VERSION ""

NS_ :

BS_:

BU_: XXX

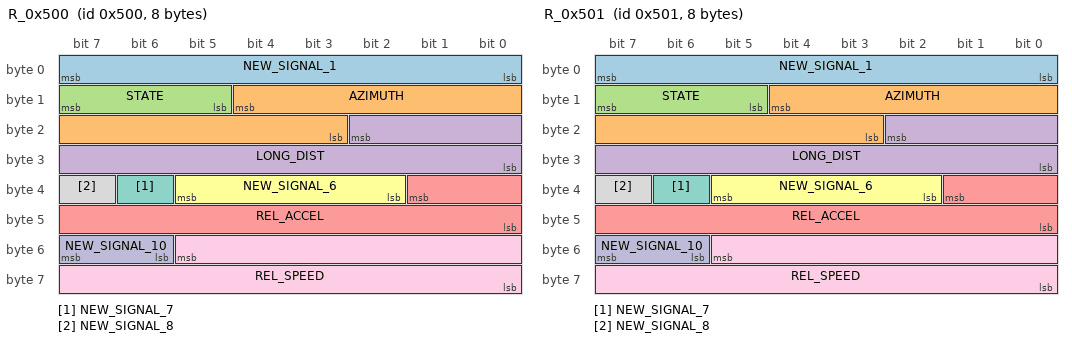
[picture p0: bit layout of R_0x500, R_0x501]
BO_ 1280 R_0x500: 8 XXX
 SG_ NEW_SIGNAL_1 : 7|8@0- (1,0) [-128|127] "" XXX
 SG_ AZIMUTH : 12|10@0- (0.2,0) [-102.4|102.2] "" XXX
 SG_ STATE : 15|3@0+ (1,0) [0|7] "" XXX
 SG_ LONG_DIST : 18|11@0+ (0.1,0) [0|204.7] "" XXX
 SG_ REL_ACCEL : 33|10@0- (0.02,0) [-10.24|10.22] "" XXX
 SG_ NEW_SIGNAL_6 : 37|4@0+ (1,0) [0|255] "" XXX
 SG_ NEW_SIGNAL_7 : 38|1@0+ (1,0) [0|1] "" XXX
 SG_ NEW_SIGNAL_8 : 39|1@0+ (1,0) [0|1] "" XXX
 SG_ REL_SPEED : 53|14@0- (0.01,0) [-81.92|81.92] "" XXX
 SG_ NEW_SIGNAL_10 : 55|2@0+ (1,0) [0|3] "" XXX

BO_ 1281 R_0x501: 8 XXX
 SG_ NEW_SIGNAL_1 : 7|8@0- (1,0) [-128|127] "" XXX
 SG_ AZIMUTH : 12|10@0- (0.2,0) [-102.4|102.2] "" XXX
 SG_ STATE : 15|3@0+ (1,0) [0|7] "" XXX
 SG_ LONG_DIST : 18|11@0+ (0.1,0) [0|204.7] "" XXX
 SG_ REL_ACCEL : 33|10@0- (0.02,0) [-10.24|10.22] "" XXX
 SG_ NEW_SIGNAL_6 : 37|4@0+ (1,0) [0|255] "" XXX
 SG_ NEW_SIGNAL_7 : 38|1@0+ (1,0) [0|1] "" XXX
 SG_ NEW_SIGNAL_8 : 39|1@0+ (1,0) [0|1] "" XXX
 SG_ REL_SPEED : 53|14@0- (0.01,0) [-81.92|81.92] "" XXX
 SG_ NEW_SIGNAL_10 : 55|2@0+ (1,0) [0|3] "" XXX

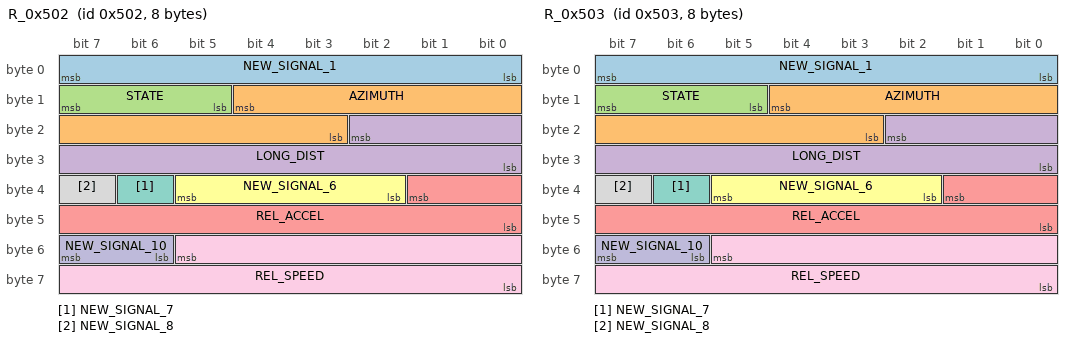
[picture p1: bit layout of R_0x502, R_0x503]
BO_ 1282 R_0x502: 8 XXX
 SG_ NEW_SIGNAL_1 : 7|8@0- (1,0) [-128|127] "" XXX
 SG_ AZIMUTH : 12|10@0- (0.2,0) [-102.4|102.2] "" XXX
 SG_ STATE : 15|3@0+ (1,0) [0|7] "" XXX
 SG_ LONG_DIST : 18|11@0+ (0.1,0) [0|204.7] "" XXX
 SG_ REL_ACCEL : 33|10@0- (0.02,0) [-10.24|10.22] "" XXX
 SG_ NEW_SIGNAL_6 : 37|4@0+ (1,0) [0|255] "" XXX
 SG_ NEW_SIGNAL_7 : 38|1@0+ (1,0) [0|1] "" XXX
 SG_ NEW_SIGNAL_8 : 39|1@0+ (1,0) [0|1] "" XXX
 SG_ REL_SPEED : 53|14@0- (0.01,0) [-81.92|81.92] "" XXX
 SG_ NEW_SIGNAL_10 : 55|2@0+ (1,0) [0|3] "" XXX

BO_ 1283 R_0x503: 8 XXX
 SG_ NEW_SIGNAL_1 : 7|8@0- (1,0) [-128|127] "" XXX
 SG_ AZIMUTH : 12|10@0- (0.2,0) [-102.4|102.2] "" XXX
 SG_ STATE : 15|3@0+ (1,0) [0|7] "" XXX
 SG_ LONG_DIST : 18|11@0+ (0.1,0) [0|204.7] "" XXX
 SG_ REL_ACCEL : 33|10@0- (0.02,0) [-10.24|10.22] "" XXX
 SG_ NEW_SIGNAL_6 : 37|4@0+ (1,0) [0|255] "" XXX
 SG_ NEW_SIGNAL_7 : 38|1@0+ (1,0) [0|1] "" XXX
 SG_ NEW_SIGNAL_8 : 39|1@0+ (1,0) [0|1] "" XXX
 SG_ REL_SPEED : 53|14@0- (0.01,0) [-81.92|81.92] "" XXX
 SG_ NEW_SIGNAL_10 : 55|2@0+ (1,0) [0|3] "" XXX

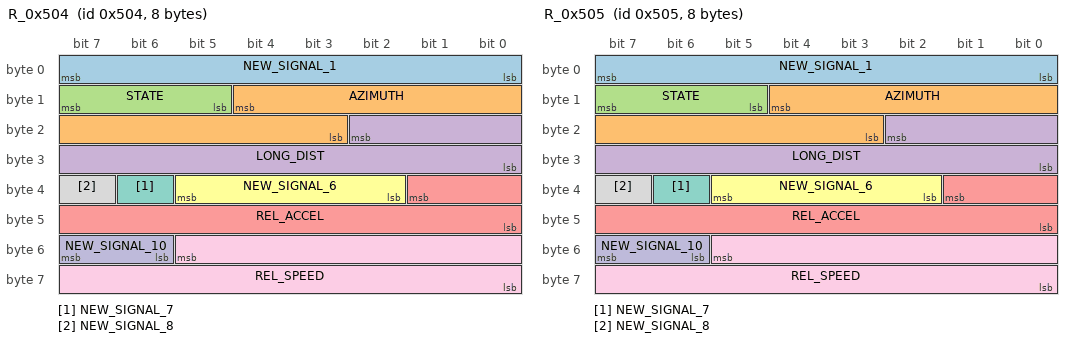
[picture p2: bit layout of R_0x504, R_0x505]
BO_ 1284 R_0x504: 8 XXX
 SG_ NEW_SIGNAL_1 : 7|8@0- (1,0) [-128|127] "" XXX
 SG_ AZIMUTH : 12|10@0- (0.2,0) [-102.4|102.2] "" XXX
 SG_ STATE : 15|3@0+ (1,0) [0|7] "" XXX
 SG_ LONG_DIST : 18|11@0+ (0.1,0) [0|204.7] "" XXX
 SG_ REL_ACCEL : 33|10@0- (0.02,0) [-10.24|10.22] "" XXX
 SG_ NEW_SIGNAL_6 : 37|4@0+ (1,0) [0|255] "" XXX
 SG_ NEW_SIGNAL_7 : 38|1@0+ (1,0) [0|1] "" XXX
 SG_ NEW_SIGNAL_8 : 39|1@0+ (1,0) [0|1] "" XXX
 SG_ REL_SPEED : 53|14@0- (0.01,0) [-81.92|81.92] "" XXX
 SG_ NEW_SIGNAL_10 : 55|2@0+ (1,0) [0|3] "" XXX

BO_ 1285 R_0x505: 8 XXX
 SG_ NEW_SIGNAL_1 : 7|8@0- (1,0) [-128|127] "" XXX
 SG_ AZIMUTH : 12|10@0- (0.2,0) [-102.4|102.2] "" XXX
 SG_ STATE : 15|3@0+ (1,0) [0|7] "" XXX
 SG_ LONG_DIST : 18|11@0+ (0.1,0) [0|204.7] "" XXX
 SG_ REL_ACCEL : 33|10@0- (0.02,0) [-10.24|10.22] "" XXX
 SG_ NEW_SIGNAL_6 : 37|4@0+ (1,0) [0|255] "" XXX
 SG_ NEW_SIGNAL_7 : 38|1@0+ (1,0) [0|1] "" XXX
 SG_ NEW_SIGNAL_8 : 39|1@0+ (1,0) [0|1] "" XXX
 SG_ REL_SPEED : 53|14@0- (0.01,0) [-81.92|81.92] "" XXX
 SG_ NEW_SIGNAL_10 : 55|2@0+ (1,0) [0|3] "" XXX

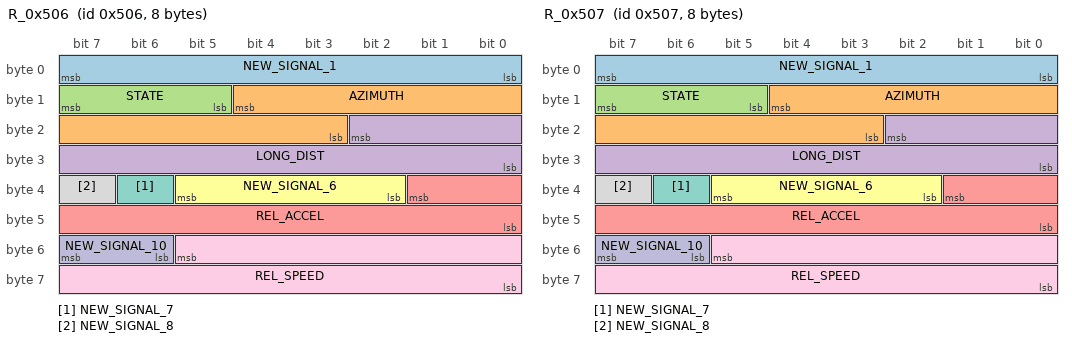
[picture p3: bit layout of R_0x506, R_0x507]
BO_ 1286 R_0x506: 8 XXX
 SG_ NEW_SIGNAL_1 : 7|8@0- (1,0) [-128|127] "" XXX
 SG_ AZIMUTH : 12|10@0- (0.2,0) [-102.4|102.2] "" XXX
 SG_ STATE : 15|3@0+ (1,0) [0|7] "" XXX
 SG_ LONG_DIST : 18|11@0+ (0.1,0) [0|204.7] "" XXX
 SG_ REL_ACCEL : 33|10@0- (0.02,0) [-10.24|10.22] "" XXX
 SG_ NEW_SIGNAL_6 : 37|4@0+ (1,0) [0|255] "" XXX
 SG_ NEW_SIGNAL_7 : 38|1@0+ (1,0) [0|1] "" XXX
 SG_ NEW_SIGNAL_8 : 39|1@0+ (1,0) [0|1] "" XXX
 SG_ REL_SPEED : 53|14@0- (0.01,0) [-81.92|81.92] "" XXX
 SG_ NEW_SIGNAL_10 : 55|2@0+ (1,0) [0|3] "" XXX

BO_ 1287 R_0x507: 8 XXX
 SG_ NEW_SIGNAL_1 : 7|8@0- (1,0) [-128|127] "" XXX
 SG_ AZIMUTH : 12|10@0- (0.2,0) [-102.4|102.2] "" XXX
 SG_ STATE : 15|3@0+ (1,0) [0|7] "" XXX
 SG_ LONG_DIST : 18|11@0+ (0.1,0) [0|204.7] "" XXX
 SG_ REL_ACCEL : 33|10@0- (0.02,0) [-10.24|10.22] "" XXX
 SG_ NEW_SIGNAL_6 : 37|4@0+ (1,0) [0|255] "" XXX
 SG_ NEW_SIGNAL_7 : 38|1@0+ (1,0) [0|1] "" XXX
 SG_ NEW_SIGNAL_8 : 39|1@0+ (1,0) [0|1] "" XXX
 SG_ REL_SPEED : 53|14@0- (0.01,0) [-81.92|81.92] "" XXX
 SG_ NEW_SIGNAL_10 : 55|2@0+ (1,0) [0|3] "" XXX

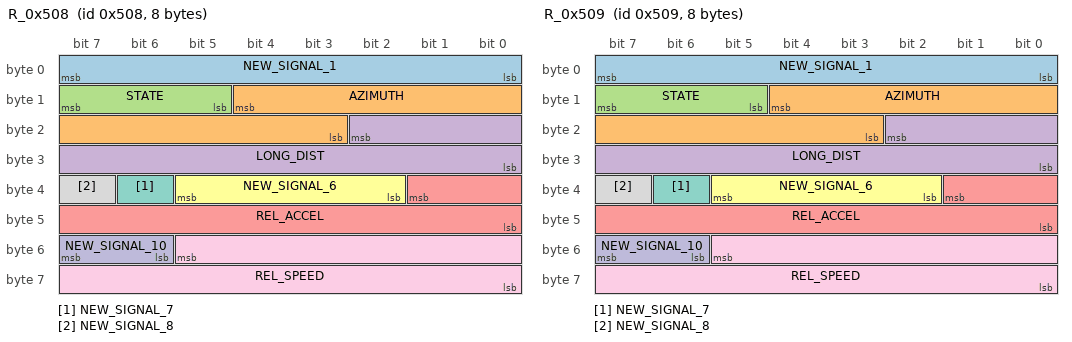
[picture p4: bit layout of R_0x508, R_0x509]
BO_ 1288 R_0x508: 8 XXX
 SG_ NEW_SIGNAL_1 : 7|8@0- (1,0) [-128|127] "" XXX
 SG_ AZIMUTH : 12|10@0- (0.2,0) [-102.4|102.2] "" XXX
 SG_ STATE : 15|3@0+ (1,0) [0|7] "" XXX
 SG_ LONG_DIST : 18|11@0+ (0.1,0) [0|204.7] "" XXX
 SG_ REL_ACCEL : 33|10@0- (0.02,0) [-10.24|10.22] "" XXX
 SG_ NEW_SIGNAL_6 : 37|4@0+ (1,0) [0|255] "" XXX
 SG_ NEW_SIGNAL_7 : 38|1@0+ (1,0) [0|1] "" XXX
 SG_ NEW_SIGNAL_8 : 39|1@0+ (1,0) [0|1] "" XXX
 SG_ REL_SPEED : 53|14@0- (0.01,0) [-81.92|81.92] "" XXX
 SG_ NEW_SIGNAL_10 : 55|2@0+ (1,0) [0|3] "" XXX

BO_ 1289 R_0x509: 8 XXX
 SG_ NEW_SIGNAL_1 : 7|8@0- (1,0) [-128|127] "" XXX
 SG_ AZIMUTH : 12|10@0- (0.2,0) [-102.4|102.2] "" XXX
 SG_ STATE : 15|3@0+ (1,0) [0|7] "" XXX
 SG_ LONG_DIST : 18|11@0+ (0.1,0) [0|204.7] "" XXX
 SG_ REL_ACCEL : 33|10@0- (0.02,0) [-10.24|10.22] "" XXX
 SG_ NEW_SIGNAL_6 : 37|4@0+ (1,0) [0|255] "" XXX
 SG_ NEW_SIGNAL_7 : 38|1@0+ (1,0) [0|1] "" XXX
 SG_ NEW_SIGNAL_8 : 39|1@0+ (1,0) [0|1] "" XXX
 SG_ REL_SPEED : 53|14@0- (0.01,0) [-81.92|81.92] "" XXX
 SG_ NEW_SIGNAL_10 : 55|2@0+ (1,0) [0|3] "" XXX

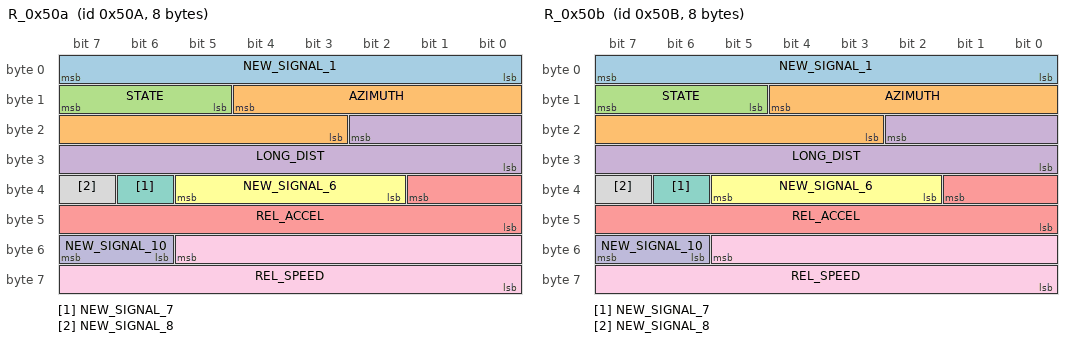
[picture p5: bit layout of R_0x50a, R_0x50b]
BO_ 1290 R_0x50a: 8 XXX
 SG_ NEW_SIGNAL_1 : 7|8@0- (1,0) [-128|127] "" XXX
 SG_ AZIMUTH : 12|10@0- (0.2,0) [-102.4|102.2] "" XXX
 SG_ STATE : 15|3@0+ (1,0) [0|7] "" XXX
 SG_ LONG_DIST : 18|11@0+ (0.1,0) [0|204.7] "" XXX
 SG_ REL_ACCEL : 33|10@0- (0.02,0) [-10.24|10.22] "" XXX
 SG_ NEW_SIGNAL_6 : 37|4@0+ (1,0) [0|255] "" XXX
 SG_ NEW_SIGNAL_7 : 38|1@0+ (1,0) [0|1] "" XXX
 SG_ NEW_SIGNAL_8 : 39|1@0+ (1,0) [0|1] "" XXX
 SG_ REL_SPEED : 53|14@0- (0.01,0) [-81.92|81.92] "" XXX
 SG_ NEW_SIGNAL_10 : 55|2@0+ (1,0) [0|3] "" XXX

BO_ 1291 R_0x50b: 8 XXX
 SG_ NEW_SIGNAL_1 : 7|8@0- (1,0) [-128|127] "" XXX
 SG_ AZIMUTH : 12|10@0- (0.2,0) [-102.4|102.2] "" XXX
 SG_ STATE : 15|3@0+ (1,0) [0|7] "" XXX
 SG_ LONG_DIST : 18|11@0+ (0.1,0) [0|204.7] "" XXX
 SG_ REL_ACCEL : 33|10@0- (0.02,0) [-10.24|10.22] "" XXX
 SG_ NEW_SIGNAL_6 : 37|4@0+ (1,0) [0|255] "" XXX
 SG_ NEW_SIGNAL_7 : 38|1@0+ (1,0) [0|1] "" XXX
 SG_ NEW_SIGNAL_8 : 39|1@0+ (1,0) [0|1] "" XXX
 SG_ REL_SPEED : 53|14@0- (0.01,0) [-81.92|81.92] "" XXX
 SG_ NEW_SIGNAL_10 : 55|2@0+ (1,0) [0|3] "" XXX

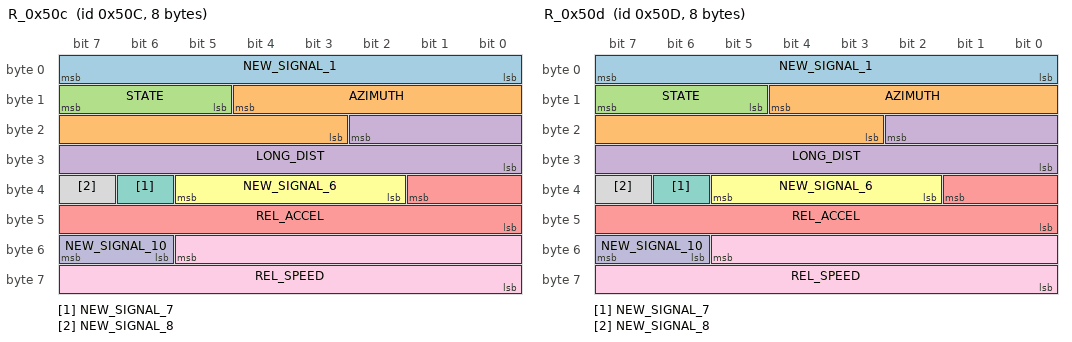
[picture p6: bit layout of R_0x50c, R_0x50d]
BO_ 1292 R_0x50c: 8 XXX
 SG_ NEW_SIGNAL_1 : 7|8@0- (1,0) [-128|127] "" XXX
 SG_ AZIMUTH : 12|10@0- (0.2,0) [-102.4|102.2] "" XXX
 SG_ STATE : 15|3@0+ (1,0) [0|7] "" XXX
 SG_ LONG_DIST : 18|11@0+ (0.1,0) [0|204.7] "" XXX
 SG_ REL_ACCEL : 33|10@0- (0.02,0) [-10.24|10.22] "" XXX
 SG_ NEW_SIGNAL_6 : 37|4@0+ (1,0) [0|255] "" XXX
 SG_ NEW_SIGNAL_7 : 38|1@0+ (1,0) [0|1] "" XXX
 SG_ NEW_SIGNAL_8 : 39|1@0+ (1,0) [0|1] "" XXX
 SG_ REL_SPEED : 53|14@0- (0.01,0) [-81.92|81.92] "" XXX
 SG_ NEW_SIGNAL_10 : 55|2@0+ (1,0) [0|3] "" XXX

BO_ 1293 R_0x50d: 8 XXX
 SG_ NEW_SIGNAL_1 : 7|8@0- (1,0) [-128|127] "" XXX
 SG_ AZIMUTH : 12|10@0- (0.2,0) [-102.4|102.2] "" XXX
 SG_ STATE : 15|3@0+ (1,0) [0|7] "" XXX
 SG_ LONG_DIST : 18|11@0+ (0.1,0) [0|204.7] "" XXX
 SG_ REL_ACCEL : 33|10@0- (0.02,0) [-10.24|10.22] "" XXX
 SG_ NEW_SIGNAL_6 : 37|4@0+ (1,0) [0|255] "" XXX
 SG_ NEW_SIGNAL_7 : 38|1@0+ (1,0) [0|1] "" XXX
 SG_ NEW_SIGNAL_8 : 39|1@0+ (1,0) [0|1] "" XXX
 SG_ REL_SPEED : 53|14@0- (0.01,0) [-81.92|81.92] "" XXX
 SG_ NEW_SIGNAL_10 : 55|2@0+ (1,0) [0|3] "" XXX

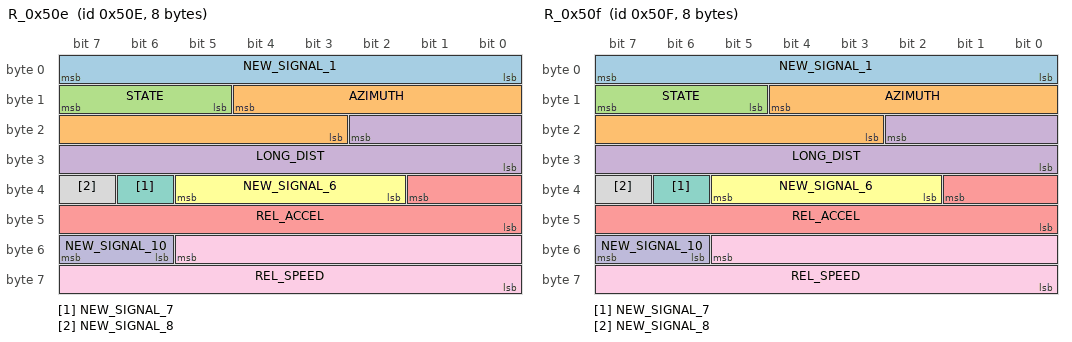
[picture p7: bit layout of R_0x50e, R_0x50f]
BO_ 1294 R_0x50e: 8 XXX
 SG_ NEW_SIGNAL_1 : 7|8@0- (1,0) [-128|127] "" XXX
 SG_ AZIMUTH : 12|10@0- (0.2,0) [-102.4|102.2] "" XXX
 SG_ STATE : 15|3@0+ (1,0) [0|7] "" XXX
 SG_ LONG_DIST : 18|11@0+ (0.1,0) [0|204.7] "" XXX
 SG_ REL_ACCEL : 33|10@0- (0.02,0) [-10.24|10.22] "" XXX
 SG_ NEW_SIGNAL_6 : 37|4@0+ (1,0) [0|255] "" XXX
 SG_ NEW_SIGNAL_7 : 38|1@0+ (1,0) [0|1] "" XXX
 SG_ NEW_SIGNAL_8 : 39|1@0+ (1,0) [0|1] "" XXX
 SG_ REL_SPEED : 53|14@0- (0.01,0) [-81.92|81.92] "" XXX
 SG_ NEW_SIGNAL_10 : 55|2@0+ (1,0) [0|3] "" XXX

BO_ 1295 R_0x50f: 8 XXX
 SG_ NEW_SIGNAL_1 : 7|8@0- (1,0) [-128|127] "" XXX
 SG_ AZIMUTH : 12|10@0- (0.2,0) [-102.4|102.2] "" XXX
 SG_ STATE : 15|3@0+ (1,0) [0|7] "" XXX
 SG_ LONG_DIST : 18|11@0+ (0.1,0) [0|204.7] "" XXX
 SG_ REL_ACCEL : 33|10@0- (0.02,0) [-10.24|10.22] "" XXX
 SG_ NEW_SIGNAL_6 : 37|4@0+ (1,0) [0|255] "" XXX
 SG_ NEW_SIGNAL_7 : 38|1@0+ (1,0) [0|1] "" XXX
 SG_ NEW_SIGNAL_8 : 39|1@0+ (1,0) [0|1] "" XXX
 SG_ REL_SPEED : 53|14@0- (0.01,0) [-81.92|81.92] "" XXX
 SG_ NEW_SIGNAL_10 : 55|2@0+ (1,0) [0|3] "" XXX

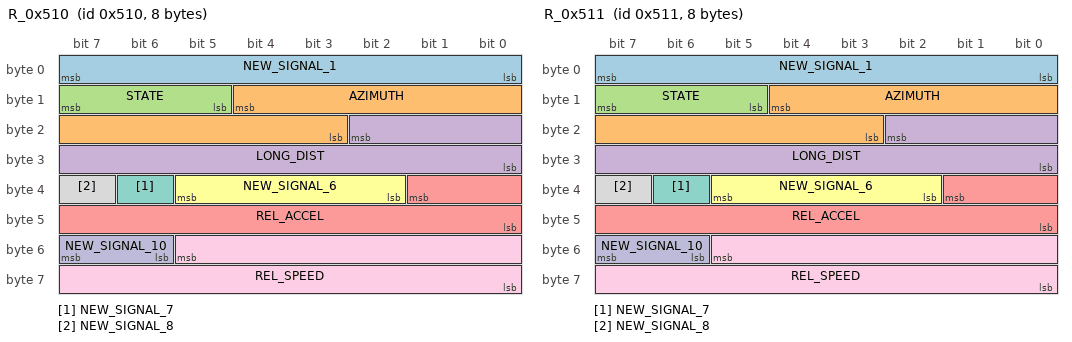
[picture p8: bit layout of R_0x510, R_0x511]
BO_ 1296 R_0x510: 8 XXX
 SG_ NEW_SIGNAL_1 : 7|8@0- (1,0) [-128|127] "" XXX
 SG_ AZIMUTH : 12|10@0- (0.2,0) [-102.4|102.2] "" XXX
 SG_ STATE : 15|3@0+ (1,0) [0|7] "" XXX
 SG_ LONG_DIST : 18|11@0+ (0.1,0) [0|204.7] "" XXX
 SG_ REL_ACCEL : 33|10@0- (0.02,0) [-10.24|10.22] "" XXX
 SG_ NEW_SIGNAL_6 : 37|4@0+ (1,0) [0|255] "" XXX
 SG_ NEW_SIGNAL_7 : 38|1@0+ (1,0) [0|1] "" XXX
 SG_ NEW_SIGNAL_8 : 39|1@0+ (1,0) [0|1] "" XXX
 SG_ REL_SPEED : 53|14@0- (0.01,0) [-81.92|81.92] "" XXX
 SG_ NEW_SIGNAL_10 : 55|2@0+ (1,0) [0|3] "" XXX

BO_ 1297 R_0x511: 8 XXX
 SG_ NEW_SIGNAL_1 : 7|8@0- (1,0) [-128|127] "" XXX
 SG_ AZIMUTH : 12|10@0- (0.2,0) [-102.4|102.2] "" XXX
 SG_ STATE : 15|3@0+ (1,0) [0|7] "" XXX
 SG_ LONG_DIST : 18|11@0+ (0.1,0) [0|204.7] "" XXX
 SG_ REL_ACCEL : 33|10@0- (0.02,0) [-10.24|10.22] "" XXX
 SG_ NEW_SIGNAL_6 : 37|4@0+ (1,0) [0|255] "" XXX
 SG_ NEW_SIGNAL_7 : 38|1@0+ (1,0) [0|1] "" XXX
 SG_ NEW_SIGNAL_8 : 39|1@0+ (1,0) [0|1] "" XXX
 SG_ REL_SPEED : 53|14@0- (0.01,0) [-81.92|81.92] "" XXX
 SG_ NEW_SIGNAL_10 : 55|2@0+ (1,0) [0|3] "" XXX

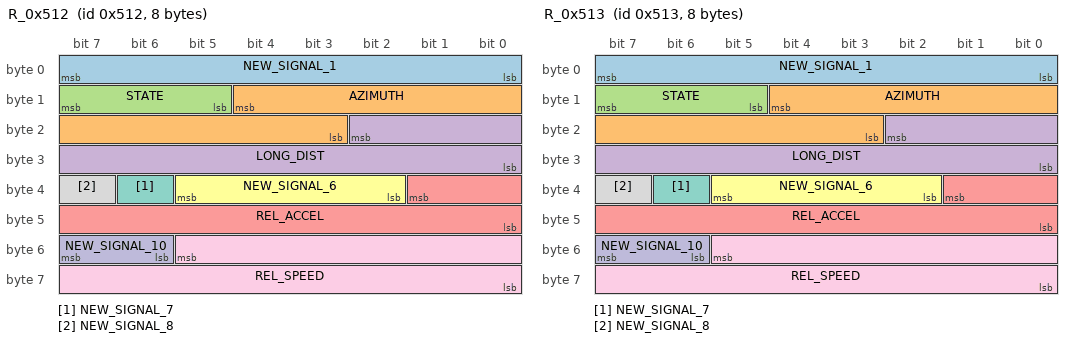
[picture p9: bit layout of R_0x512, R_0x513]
BO_ 1298 R_0x512: 8 XXX
 SG_ NEW_SIGNAL_1 : 7|8@0- (1,0) [-128|127] "" XXX
 SG_ AZIMUTH : 12|10@0- (0.2,0) [-102.4|102.2] "" XXX
 SG_ STATE : 15|3@0+ (1,0) [0|7] "" XXX
 SG_ LONG_DIST : 18|11@0+ (0.1,0) [0|204.7] "" XXX
 SG_ REL_ACCEL : 33|10@0- (0.02,0) [-10.24|10.22] "" XXX
 SG_ NEW_SIGNAL_6 : 37|4@0+ (1,0) [0|255] "" XXX
 SG_ NEW_SIGNAL_7 : 38|1@0+ (1,0) [0|1] "" XXX
 SG_ NEW_SIGNAL_8 : 39|1@0+ (1,0) [0|1] "" XXX
 SG_ REL_SPEED : 53|14@0- (0.01,0) [-81.92|81.92] "" XXX
 SG_ NEW_SIGNAL_10 : 55|2@0+ (1,0) [0|3] "" XXX

BO_ 1299 R_0x513: 8 XXX
 SG_ NEW_SIGNAL_1 : 7|8@0- (1,0) [-128|127] "" XXX
 SG_ AZIMUTH : 12|10@0- (0.2,0) [-102.4|102.2] "" XXX
 SG_ STATE : 15|3@0+ (1,0) [0|7] "" XXX
 SG_ LONG_DIST : 18|11@0+ (0.1,0) [0|204.7] "" XXX
 SG_ REL_ACCEL : 33|10@0- (0.02,0) [-10.24|10.22] "" XXX
 SG_ NEW_SIGNAL_6 : 37|4@0+ (1,0) [0|255] "" XXX
 SG_ NEW_SIGNAL_7 : 38|1@0+ (1,0) [0|1] "" XXX
 SG_ NEW_SIGNAL_8 : 39|1@0+ (1,0) [0|1] "" XXX
 SG_ REL_SPEED : 53|14@0- (0.01,0) [-81.92|81.92] "" XXX
 SG_ NEW_SIGNAL_10 : 55|2@0+ (1,0) [0|3] "" XXX

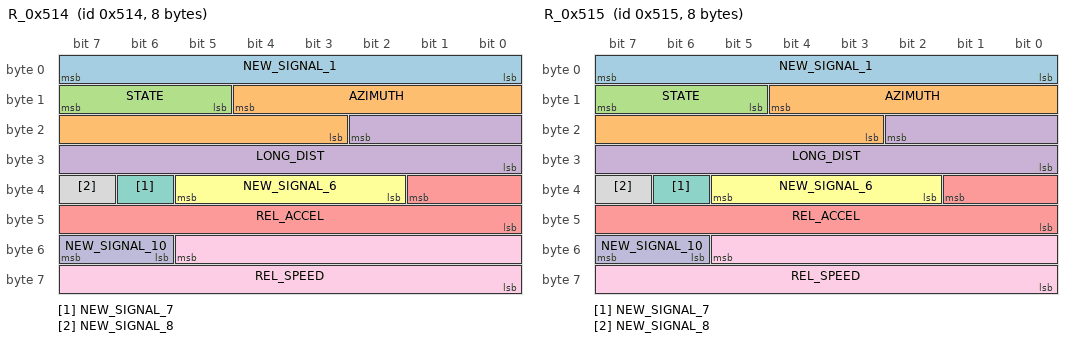
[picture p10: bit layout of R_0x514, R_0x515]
BO_ 1300 R_0x514: 8 XXX
 SG_ NEW_SIGNAL_1 : 7|8@0- (1,0) [-128|127] "" XXX
 SG_ AZIMUTH : 12|10@0- (0.2,0) [-102.4|102.2] "" XXX
 SG_ STATE : 15|3@0+ (1,0) [0|7] "" XXX
 SG_ LONG_DIST : 18|11@0+ (0.1,0) [0|204.7] "" XXX
 SG_ REL_ACCEL : 33|10@0- (0.02,0) [-10.24|10.22] "" XXX
 SG_ NEW_SIGNAL_6 : 37|4@0+ (1,0) [0|255] "" XXX
 SG_ NEW_SIGNAL_7 : 38|1@0+ (1,0) [0|1] "" XXX
 SG_ NEW_SIGNAL_8 : 39|1@0+ (1,0) [0|1] "" XXX
 SG_ REL_SPEED : 53|14@0- (0.01,0) [-81.92|81.92] "" XXX
 SG_ NEW_SIGNAL_10 : 55|2@0+ (1,0) [0|3] "" XXX

BO_ 1301 R_0x515: 8 XXX
 SG_ NEW_SIGNAL_1 : 7|8@0- (1,0) [-128|127] "" XXX
 SG_ AZIMUTH : 12|10@0- (0.2,0) [-102.4|102.2] "" XXX
 SG_ STATE : 15|3@0+ (1,0) [0|7] "" XXX
 SG_ LONG_DIST : 18|11@0+ (0.1,0) [0|204.7] "" XXX
 SG_ REL_ACCEL : 33|10@0- (0.02,0) [-10.24|10.22] "" XXX
 SG_ NEW_SIGNAL_6 : 37|4@0+ (1,0) [0|255] "" XXX
 SG_ NEW_SIGNAL_7 : 38|1@0+ (1,0) [0|1] "" XXX
 SG_ NEW_SIGNAL_8 : 39|1@0+ (1,0) [0|1] "" XXX
 SG_ REL_SPEED : 53|14@0- (0.01,0) [-81.92|81.92] "" XXX
 SG_ NEW_SIGNAL_10 : 55|2@0+ (1,0) [0|3] "" XXX

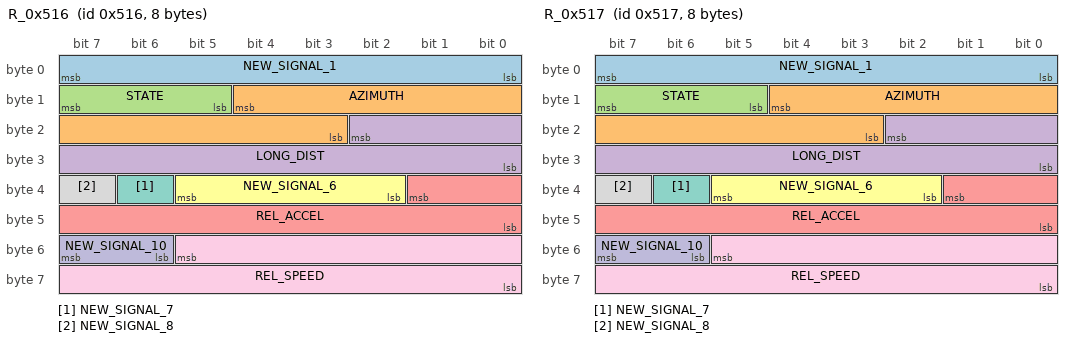
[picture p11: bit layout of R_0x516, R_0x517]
BO_ 1302 R_0x516: 8 XXX
 SG_ NEW_SIGNAL_1 : 7|8@0- (1,0) [-128|127] "" XXX
 SG_ AZIMUTH : 12|10@0- (0.2,0) [-102.4|102.2] "" XXX
 SG_ STATE : 15|3@0+ (1,0) [0|7] "" XXX
 SG_ LONG_DIST : 18|11@0+ (0.1,0) [0|204.7] "" XXX
 SG_ REL_ACCEL : 33|10@0- (0.02,0) [-10.24|10.22] "" XXX
 SG_ NEW_SIGNAL_6 : 37|4@0+ (1,0) [0|255] "" XXX
 SG_ NEW_SIGNAL_7 : 38|1@0+ (1,0) [0|1] "" XXX
 SG_ NEW_SIGNAL_8 : 39|1@0+ (1,0) [0|1] "" XXX
 SG_ REL_SPEED : 53|14@0- (0.01,0) [-81.92|81.92] "" XXX
 SG_ NEW_SIGNAL_10 : 55|2@0+ (1,0) [0|3] "" XXX

BO_ 1303 R_0x517: 8 XXX
 SG_ NEW_SIGNAL_1 : 7|8@0- (1,0) [-128|127] "" XXX
 SG_ AZIMUTH : 12|10@0- (0.2,0) [-102.4|102.2] "" XXX
 SG_ STATE : 15|3@0+ (1,0) [0|7] "" XXX
 SG_ LONG_DIST : 18|11@0+ (0.1,0) [0|204.7] "" XXX
 SG_ REL_ACCEL : 33|10@0- (0.02,0) [-10.24|10.22] "" XXX
 SG_ NEW_SIGNAL_6 : 37|4@0+ (1,0) [0|255] "" XXX
 SG_ NEW_SIGNAL_7 : 38|1@0+ (1,0) [0|1] "" XXX
 SG_ NEW_SIGNAL_8 : 39|1@0+ (1,0) [0|1] "" XXX
 SG_ REL_SPEED : 53|14@0- (0.01,0) [-81.92|81.92] "" XXX
 SG_ NEW_SIGNAL_10 : 55|2@0+ (1,0) [0|3] "" XXX

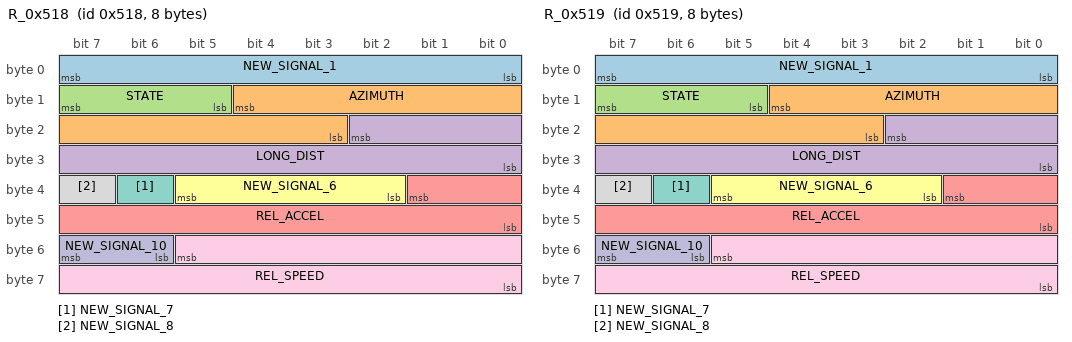
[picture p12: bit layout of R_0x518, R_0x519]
BO_ 1304 R_0x518: 8 XXX
 SG_ NEW_SIGNAL_1 : 7|8@0- (1,0) [-128|127] "" XXX
 SG_ AZIMUTH : 12|10@0- (0.2,0) [-102.4|102.2] "" XXX
 SG_ STATE : 15|3@0+ (1,0) [0|7] "" XXX
 SG_ LONG_DIST : 18|11@0+ (0.1,0) [0|204.7] "" XXX
 SG_ REL_ACCEL : 33|10@0- (0.02,0) [-10.24|10.22] "" XXX
 SG_ NEW_SIGNAL_6 : 37|4@0+ (1,0) [0|255] "" XXX
 SG_ NEW_SIGNAL_7 : 38|1@0+ (1,0) [0|1] "" XXX
 SG_ NEW_SIGNAL_8 : 39|1@0+ (1,0) [0|1] "" XXX
 SG_ REL_SPEED : 53|14@0- (0.01,0) [-81.92|81.92] "" XXX
 SG_ NEW_SIGNAL_10 : 55|2@0+ (1,0) [0|3] "" XXX

BO_ 1305 R_0x519: 8 XXX
 SG_ NEW_SIGNAL_1 : 7|8@0- (1,0) [-128|127] "" XXX
 SG_ AZIMUTH : 12|10@0- (0.2,0) [-102.4|102.2] "" XXX
 SG_ STATE : 15|3@0+ (1,0) [0|7] "" XXX
 SG_ LONG_DIST : 18|11@0+ (0.1,0) [0|204.7] "" XXX
 SG_ REL_ACCEL : 33|10@0- (0.02,0) [-10.24|10.22] "" XXX
 SG_ NEW_SIGNAL_6 : 37|4@0+ (1,0) [0|255] "" XXX
 SG_ NEW_SIGNAL_7 : 38|1@0+ (1,0) [0|1] "" XXX
 SG_ NEW_SIGNAL_8 : 39|1@0+ (1,0) [0|1] "" XXX
 SG_ REL_SPEED : 53|14@0- (0.01,0) [-81.92|81.92] "" XXX
 SG_ NEW_SIGNAL_10 : 55|2@0+ (1,0) [0|3] "" XXX

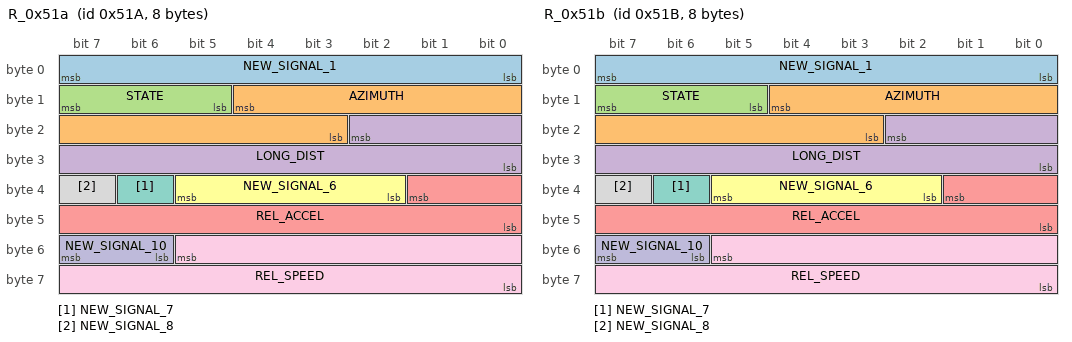
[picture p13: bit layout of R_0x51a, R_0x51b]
BO_ 1306 R_0x51a: 8 XXX
 SG_ NEW_SIGNAL_1 : 7|8@0- (1,0) [-128|127] "" XXX
 SG_ AZIMUTH : 12|10@0- (0.2,0) [-102.4|102.2] "" XXX
 SG_ STATE : 15|3@0+ (1,0) [0|7] "" XXX
 SG_ LONG_DIST : 18|11@0+ (0.1,0) [0|204.7] "" XXX
 SG_ REL_ACCEL : 33|10@0- (0.02,0) [-10.24|10.22] "" XXX
 SG_ NEW_SIGNAL_6 : 37|4@0+ (1,0) [0|255] "" XXX
 SG_ NEW_SIGNAL_7 : 38|1@0+ (1,0) [0|1] "" XXX
 SG_ NEW_SIGNAL_8 : 39|1@0+ (1,0) [0|1] "" XXX
 SG_ REL_SPEED : 53|14@0- (0.01,0) [-81.92|81.92] "" XXX
 SG_ NEW_SIGNAL_10 : 55|2@0+ (1,0) [0|3] "" XXX

BO_ 1307 R_0x51b: 8 XXX
 SG_ NEW_SIGNAL_1 : 7|8@0- (1,0) [-128|127] "" XXX
 SG_ AZIMUTH : 12|10@0- (0.2,0) [-102.4|102.2] "" XXX
 SG_ STATE : 15|3@0+ (1,0) [0|7] "" XXX
 SG_ LONG_DIST : 18|11@0+ (0.1,0) [0|204.7] "" XXX
 SG_ REL_ACCEL : 33|10@0- (0.02,0) [-10.24|10.22] "" XXX
 SG_ NEW_SIGNAL_6 : 37|4@0+ (1,0) [0|255] "" XXX
 SG_ NEW_SIGNAL_7 : 38|1@0+ (1,0) [0|1] "" XXX
 SG_ NEW_SIGNAL_8 : 39|1@0+ (1,0) [0|1] "" XXX
 SG_ REL_SPEED : 53|14@0- (0.01,0) [-81.92|81.92] "" XXX
 SG_ NEW_SIGNAL_10 : 55|2@0+ (1,0) [0|3] "" XXX

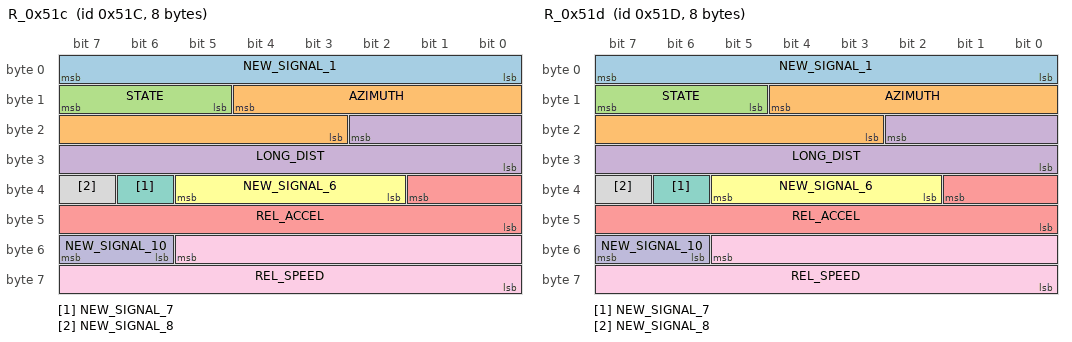
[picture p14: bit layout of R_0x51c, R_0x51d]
BO_ 1308 R_0x51c: 8 XXX
 SG_ NEW_SIGNAL_1 : 7|8@0- (1,0) [-128|127] "" XXX
 SG_ AZIMUTH : 12|10@0- (0.2,0) [-102.4|102.2] "" XXX
 SG_ STATE : 15|3@0+ (1,0) [0|7] "" XXX
 SG_ LONG_DIST : 18|11@0+ (0.1,0) [0|204.7] "" XXX
 SG_ REL_ACCEL : 33|10@0- (0.02,0) [-10.24|10.22] "" XXX
 SG_ NEW_SIGNAL_6 : 37|4@0+ (1,0) [0|255] "" XXX
 SG_ NEW_SIGNAL_7 : 38|1@0+ (1,0) [0|1] "" XXX
 SG_ NEW_SIGNAL_8 : 39|1@0+ (1,0) [0|1] "" XXX
 SG_ REL_SPEED : 53|14@0- (0.01,0) [-81.92|81.92] "" XXX
 SG_ NEW_SIGNAL_10 : 55|2@0+ (1,0) [0|3] "" XXX

BO_ 1309 R_0x51d: 8 XXX
 SG_ NEW_SIGNAL_1 : 7|8@0- (1,0) [-128|127] "" XXX
 SG_ AZIMUTH : 12|10@0- (0.2,0) [-102.4|102.2] "" XXX
 SG_ STATE : 15|3@0+ (1,0) [0|7] "" XXX
 SG_ LONG_DIST : 18|11@0+ (0.1,0) [0|204.7] "" XXX
 SG_ REL_ACCEL : 33|10@0- (0.02,0) [-10.24|10.22] "" XXX
 SG_ NEW_SIGNAL_6 : 37|4@0+ (1,0) [0|255] "" XXX
 SG_ NEW_SIGNAL_7 : 38|1@0+ (1,0) [0|1] "" XXX
 SG_ NEW_SIGNAL_8 : 39|1@0+ (1,0) [0|1] "" XXX
 SG_ REL_SPEED : 53|14@0- (0.01,0) [-81.92|81.92] "" XXX
 SG_ NEW_SIGNAL_10 : 55|2@0+ (1,0) [0|3] "" XXX

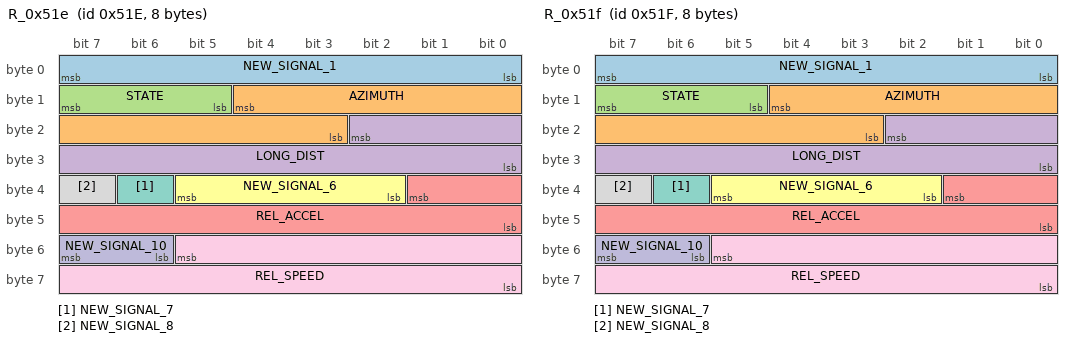
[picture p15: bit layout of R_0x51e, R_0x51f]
BO_ 1310 R_0x51e: 8 XXX
 SG_ NEW_SIGNAL_1 : 7|8@0- (1,0) [-128|127] "" XXX
 SG_ AZIMUTH : 12|10@0- (0.2,0) [-102.4|102.2] "" XXX
 SG_ STATE : 15|3@0+ (1,0) [0|7] "" XXX
 SG_ LONG_DIST : 18|11@0+ (0.1,0) [0|204.7] "" XXX
 SG_ REL_ACCEL : 33|10@0- (0.02,0) [-10.24|10.22] "" XXX
 SG_ NEW_SIGNAL_6 : 37|4@0+ (1,0) [0|255] "" XXX
 SG_ NEW_SIGNAL_7 : 38|1@0+ (1,0) [0|1] "" XXX
 SG_ NEW_SIGNAL_8 : 39|1@0+ (1,0) [0|1] "" XXX
 SG_ REL_SPEED : 53|14@0- (0.01,0) [-81.92|81.92] "" XXX
 SG_ NEW_SIGNAL_10 : 55|2@0+ (1,0) [0|3] "" XXX

BO_ 1311 R_0x51f: 8 XXX
 SG_ NEW_SIGNAL_1 : 7|8@0- (1,0) [-128|127] "" XXX
 SG_ AZIMUTH : 12|10@0- (0.2,0) [-102.4|102.2] "" XXX
 SG_ STATE : 15|3@0+ (1,0) [0|7] "" XXX
 SG_ LONG_DIST : 18|11@0+ (0.1,0) [0|204.7] "" XXX
 SG_ REL_ACCEL : 33|10@0- (0.02,0) [-10.24|10.22] "" XXX
 SG_ NEW_SIGNAL_6 : 37|4@0+ (1,0) [0|255] "" XXX
 SG_ NEW_SIGNAL_7 : 38|1@0+ (1,0) [0|1] "" XXX
 SG_ NEW_SIGNAL_8 : 39|1@0+ (1,0) [0|1] "" XXX
 SG_ REL_SPEED : 53|14@0- (0.01,0) [-81.92|81.92] "" XXX
 SG_ NEW_SIGNAL_10 : 55|2@0+ (1,0) [0|3] "" XXX
